VERSION ""

NS_ :

BS_:

BU_: Bms INV U2C VCU

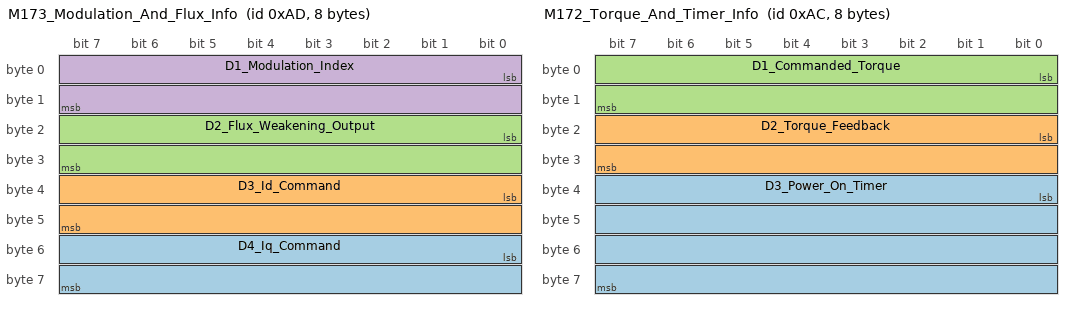
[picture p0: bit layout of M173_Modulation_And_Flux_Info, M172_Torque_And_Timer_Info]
BO_ 173 M173_Modulation_And_Flux_Info: 8 INV
 SG_ D4_Iq_Command : 48|16@1- (0.1,0) [-3276.8|3276.7] "A" Vector__XXX
 SG_ D3_Id_Command : 32|16@1- (0.1,0) [-3276.8|3276.7] "A" Vector__XXX
 SG_ D2_Flux_Weakening_Output : 16|16@1- (0.1,0) [-3276.8|3276.7] "A" Vector__XXX
 SG_ D1_Modulation_Index : 0|16@1- (0.0001,0) [-3.2768|3.2767] "" Vector__XXX

BO_ 172 M172_Torque_And_Timer_Info: 8 INV
 SG_ D3_Power_On_Timer : 32|32@1+ (0.003,0) [0|12884800] "Sec" Vector__XXX
 SG_ D2_Torque_Feedback : 16|16@1- (0.1,0) [-3276.8|3276.7] "Nm" Vector__XXX
 SG_ D1_Commanded_Torque : 0|16@1- (0.1,0) [-3276.8|3276.7] "Nm" Vector__XXX

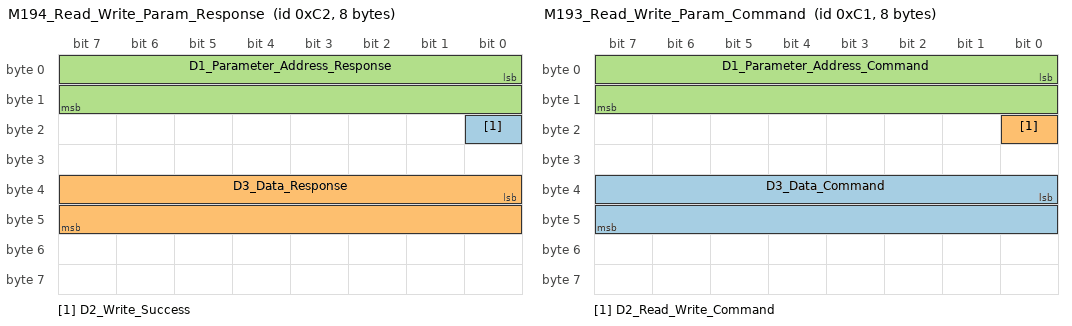
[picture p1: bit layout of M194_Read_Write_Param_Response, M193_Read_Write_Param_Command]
BO_ 194 M194_Read_Write_Param_Response: 8 INV
 SG_ D2_Write_Success : 16|1@1+ (1,0) [0|1] "" Vector__XXX
 SG_ D3_Data_Response : 32|16@1- (1,0) [-32768|32767] "" Vector__XXX
 SG_ D1_Parameter_Address_Response : 0|16@1+ (1,0) [0|65535] "" Vector__XXX

BO_ 193 M193_Read_Write_Param_Command: 8 VCU
 SG_ D3_Data_Command : 32|16@1- (1,0) [-32768|32767] "" Vector__XXX
 SG_ D2_Read_Write_Command : 16|1@1+ (1,0) [0|1] "" Vector__XXX
 SG_ D1_Parameter_Address_Command : 0|16@1+ (1,0) [0|65535] "" Vector__XXX

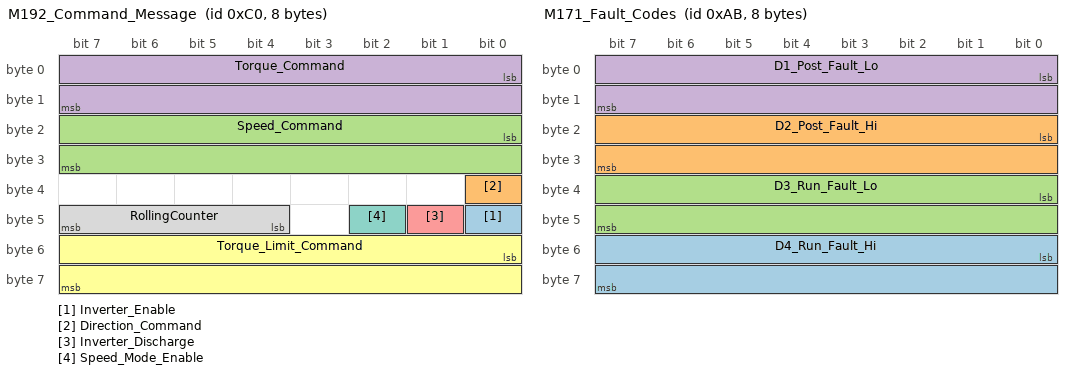
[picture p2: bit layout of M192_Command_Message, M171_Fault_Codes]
BO_ 192 M192_Command_Message: 8 VCU
 SG_ Inverter_Enable : 40|1@1+ (1,0) [0|1] "Bit" Vector__XXX
 SG_ Direction_Command : 32|1@1+ (1,0) [0|1] "Bit" Vector__XXX
 SG_ Speed_Command : 16|16@1- (1,0) [-32768|32767] "rpm" Vector__XXX
 SG_ Torque_Command : 0|16@1- (0.1,0) [-3276.8|3276.7] "Nm" Vector__XXX
 SG_ Inverter_Discharge : 41|1@1+ (1,0) [0|1] "Bit" Vector__XXX
 SG_ Torque_Limit_Command : 48|16@1- (0.1,0) [-3276.8|3276.7] "Nm" Vector__XXX
 SG_ Speed_Mode_Enable : 42|1@1+ (1,0) [0|1] "Bit" Vector__XXX
 SG_ RollingCounter : 44|4@1+ (1,0) [0|15] "Bits" Vector__XXX

BO_ 171 M171_Fault_Codes: 8 INV
 SG_ D4_Run_Fault_Hi : 48|16@1+ (1,0) [0|65535] "" Vector__XXX
 SG_ D2_Post_Fault_Hi : 16|16@1+ (1,0) [0|65535] "" Vector__XXX
 SG_ D3_Run_Fault_Lo : 32|16@1+ (1,0) [0|65535] "" Vector__XXX
 SG_ D1_Post_Fault_Lo : 0|16@1+ (1,0) [0|65535] "" Vector__XXX

BO_ 170 M170_Internal_States: 8 INV
 SG_ D7_Direction_Command : 56|1@1+ (1,0) [0|1] "" Vector__XXX
 SG_ D6_Inverter_Enable_State : 48|1@1+ (1,0) [0|1] "" Vector__XXX
 SG_ D3_Relay_3_Status : 26|1@1+ (1,0) [0|1] "" Vector__XXX
 SG_ D3_Relay_4_Status : 27|1@1+ (1,0) [0|1] "" Vector__XXX
 SG_ D3_Relay_2_Status : 25|1@1+ (1,0) [0|1] "" Vector__XXX
 SG_ D4_Inverter_Run_Mode : 32|1@1+ (1,0) [0|1] "" Vector__XXX
 SG_ D5_Inverter_Command_Mode : 40|1@1+ (1,0) [0|1] "" Vector__XXX
 SG_ D3_Relay_1_Status : 24|1@1+ (1,0) [0|1] "" Vector__XXX
 SG_ D2_Inverter_State : 16|8@1+ (1,0) [0|255] "" Vector__XXX
 SG_ D1_VSM_State : 0|8@1+ (1,0) [0|15] "" Vector__XXX
 SG_ D6_Inverter_Enable_Lockout : 55|1@1+ (1,0) [0|1] "" Vector__XXX
 SG_ D4_Inverter_Discharge_State : 37|3@1+ (1,0) [0|7] "" Vector__XXX
 SG_ D3_Relay_5_Status : 28|1@1+ (1,0) [0|1] "" Vector__XXX
 SG_ D3_Relay_6_Status : 29|1@1+ (1,0) [0|1] "" Vector__XXX
 SG_ D7_BMS_Active : 57|1@1+ (1,0) [0|1] "" Vector__XXX
 SG_ D7_BMS_Torque_Limiting : 58|1@1+ (1,0) [0|1] "" Vector__XXX
 SG_ D7_Max_Speed_Limiting : 59|1@1+ (1,0) [0|1] "" Vector__XXX
 SG_ D7_Low_Speed_Limiting : 61|1@1+ (1,0) [0|1] "" Vector__XXX
 SG_ D5_Rolling_Counter : 44|4@1+ (1,0) [0|15] "" Vector__XXX
 SG_ D1_PWM_Frequency : 8|8@1+ (1,0) [0|255] "kHz" Vector__XXX
 SG_ D6_Start_Mode_Active : 54|1@1+ (1,0) [0|1] "" Vector__XXX

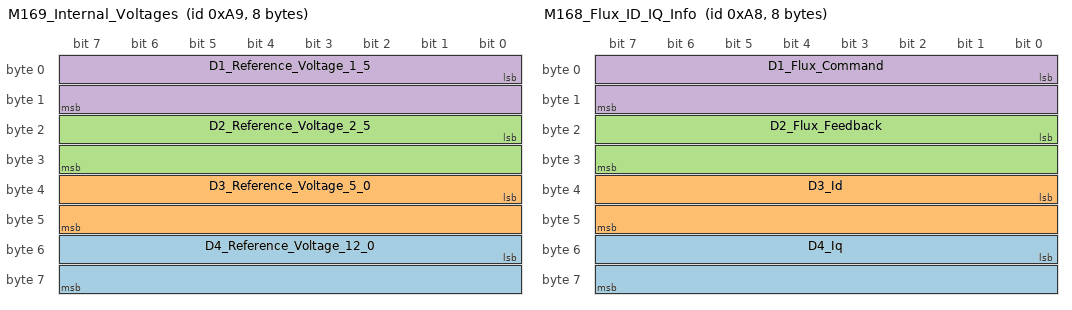
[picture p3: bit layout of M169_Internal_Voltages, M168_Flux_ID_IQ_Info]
BO_ 169 M169_Internal_Voltages: 8 INV
 SG_ D4_Reference_Voltage_12_0 : 48|16@1- (0.01,0) [-327.68|327.67] "V" Vector__XXX
 SG_ D3_Reference_Voltage_5_0 : 32|16@1- (0.01,0) [-327.68|327.67] "V" Vector__XXX
 SG_ D2_Reference_Voltage_2_5 : 16|16@1- (0.01,0) [-327.68|327.67] "V" Vector__XXX
 SG_ D1_Reference_Voltage_1_5 : 0|16@1- (0.01,0) [-327.68|327.67] "V" Vector__XXX

BO_ 168 M168_Flux_ID_IQ_Info: 8 INV
 SG_ D4_Iq : 48|16@1- (0.1,0) [-3276.8|3276.7] "A" Vector__XXX
 SG_ D3_Id : 32|16@1- (0.1,0) [-3276.8|3276.7] "A" Vector__XXX
 SG_ D2_Flux_Feedback : 16|16@1- (0.001,0) [-32.768|32.767] "Wb" Vector__XXX
 SG_ D1_Flux_Command : 0|16@1- (0.001,0) [-32.768|32.767] "Wb" Vector__XXX

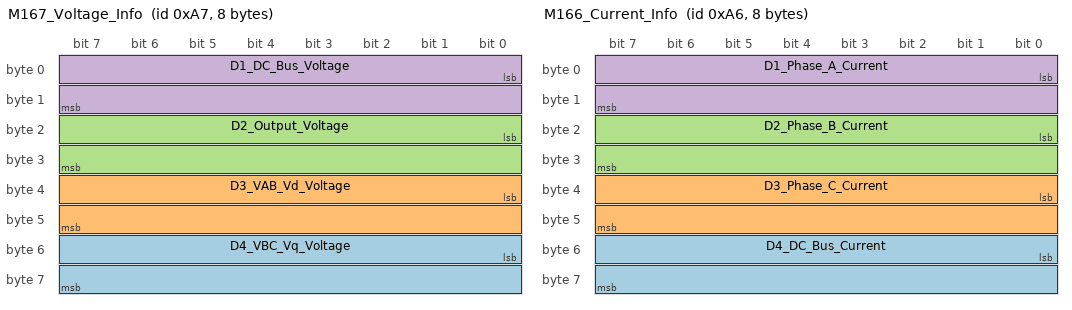
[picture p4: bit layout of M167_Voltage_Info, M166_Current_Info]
BO_ 167 M167_Voltage_Info: 8 INV
 SG_ D4_VBC_Vq_Voltage : 48|16@1- (0.1,0) [-3276.8|3276.7] "V" Vector__XXX
 SG_ D3_VAB_Vd_Voltage : 32|16@1- (0.1,0) [-3276.8|3276.7] "V" Vector__XXX
 SG_ D2_Output_Voltage : 16|16@1- (0.1,0) [-3276.8|3276.7] "V" Vector__XXX
 SG_ D1_DC_Bus_Voltage : 0|16@1- (0.1,0) [-3276.8|3276.7] "V" Vector__XXX

BO_ 166 M166_Current_Info: 8 INV
 SG_ D4_DC_Bus_Current : 48|16@1- (0.1,0) [-3276.8|3276.7] "A" Vector__XXX
 SG_ D3_Phase_C_Current : 32|16@1- (0.1,0) [-3276.8|3276.7] "A" Vector__XXX
 SG_ D2_Phase_B_Current : 16|16@1- (0.1,0) [-3276.8|3276.7] "A" Vector__XXX
 SG_ D1_Phase_A_Current : 0|16@1- (0.1,0) [-3276.8|3276.7] "A" Vector__XXX

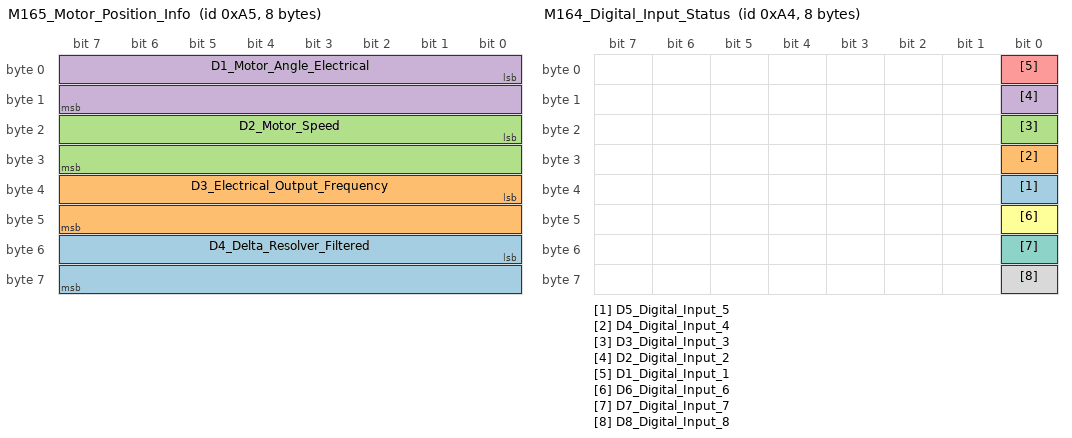
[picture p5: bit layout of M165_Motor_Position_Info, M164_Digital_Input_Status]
BO_ 165 M165_Motor_Position_Info: 8 INV
 SG_ D4_Delta_Resolver_Filtered : 48|16@1- (0.1,0) [-3276.8|3276.7] "deg" Vector__XXX
 SG_ D3_Electrical_Output_Frequency : 32|16@1- (0.1,0) [-3276.8|3276.7] "hz" Vector__XXX
 SG_ D2_Motor_Speed : 16|16@1- (1,0) [-32768|32767] "rpm" Vector__XXX
 SG_ D1_Motor_Angle_Electrical : 0|16@1+ (0.1,0) [0|6553.5] "deg" Vector__XXX

BO_ 164 M164_Digital_Input_Status: 8 INV
 SG_ D5_Digital_Input_5 : 32|1@1+ (1,0) [0|1] "boolean" Vector__XXX
 SG_ D4_Digital_Input_4 : 24|1@1+ (1,0) [0|1] "boolean" Vector__XXX
 SG_ D3_Digital_Input_3 : 16|1@1+ (1,0) [0|1] "boolean" Vector__XXX
 SG_ D2_Digital_Input_2 : 8|1@1+ (1,0) [0|1] "boolean" Vector__XXX
 SG_ D1_Digital_Input_1 : 0|1@1+ (1,0) [0|1] "boolean" Vector__XXX
 SG_ D6_Digital_Input_6 : 40|1@1+ (1,0) [0|1] "boolean" Vector__XXX
 SG_ D7_Digital_Input_7 : 48|1@1+ (1,0) [0|1] "boolean" Vector__XXX
 SG_ D8_Digital_Input_8 : 56|1@1+ (1,0) [0|1] "boolean" Vector__XXX

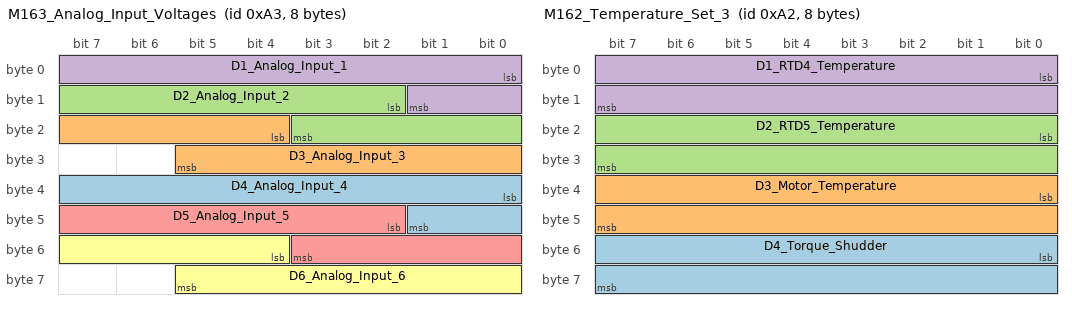
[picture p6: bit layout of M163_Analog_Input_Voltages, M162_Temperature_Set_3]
BO_ 163 M163_Analog_Input_Voltages: 8 INV
 SG_ D4_Analog_Input_4 : 32|10@1+ (0.01,0) [0|10.23] "V" Vector__XXX
 SG_ D3_Analog_Input_3 : 20|10@1+ (0.01,0) [0|10.23] "V" Vector__XXX
 SG_ D2_Analog_Input_2 : 10|10@1+ (0.01,0) [0|10.23] "V" Vector__XXX
 SG_ D1_Analog_Input_1 : 0|10@1+ (0.01,0) [0|10.23] "V" Vector__XXX
 SG_ D5_Analog_Input_5 : 42|10@1+ (0.01,0) [0|10.23] "V" Vector__XXX
 SG_ D6_Analog_Input_6 : 52|10@1+ (0.01,0) [0|10.23] "V" Vector__XXX

BO_ 162 M162_Temperature_Set_3: 8 INV
 SG_ D4_Torque_Shudder : 48|16@1- (0.1,0) [-3276.8|3276.7] "Nm" Vector__XXX
 SG_ D3_Motor_Temperature : 32|16@1- (0.1,0) [-3276.8|3276.7] "degC" Vector__XXX
 SG_ D2_RTD5_Temperature : 16|16@1- (0.1,0) [-3276.8|3276.7] "degC" Vector__XXX
 SG_ D1_RTD4_Temperature : 0|16@1- (0.1,0) [-3276.8|3276.7] "degC" Vector__XXX

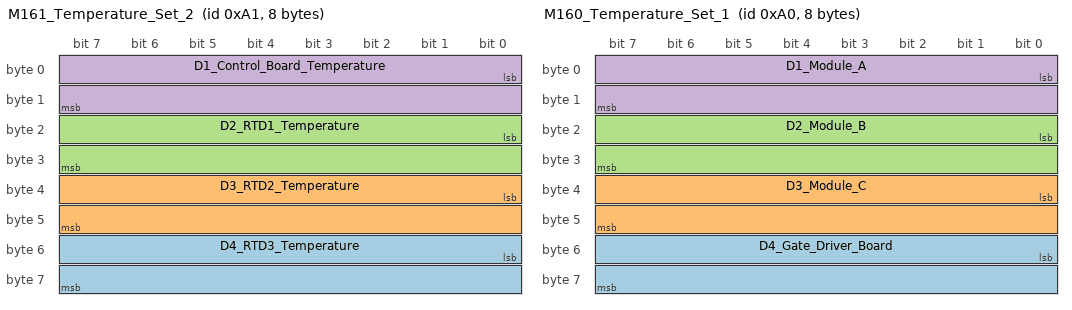
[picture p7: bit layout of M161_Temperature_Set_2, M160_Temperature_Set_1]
BO_ 161 M161_Temperature_Set_2: 8 INV
 SG_ D4_RTD3_Temperature : 48|16@1- (0.1,0) [-3276.8|3276.7] "degC" Vector__XXX
 SG_ D3_RTD2_Temperature : 32|16@1- (0.1,0) [-3276.8|3276.7] "degC" Vector__XXX
 SG_ D2_RTD1_Temperature : 16|16@1- (0.1,0) [-3276.8|3276.7] "degC" Vector__XXX
 SG_ D1_Control_Board_Temperature : 0|16@1- (0.1,0) [-3276.8|3276.7] "degC" Vector__XXX

BO_ 160 M160_Temperature_Set_1: 8 INV
 SG_ D4_Gate_Driver_Board : 48|16@1- (0.1,0) [-3276.8|3276.7] "degC" Vector__XXX
 SG_ D3_Module_C : 32|16@1- (0.1,0) [-3276.8|3276.7] "degC" Vector__XXX
 SG_ D2_Module_B : 16|16@1- (0.1,0) [-3276.8|3276.7] "degC" Vector__XXX
 SG_ D1_Module_A : 0|16@1- (0.1,0) [-3276.8|3276.7] "degC" Vector__XXX

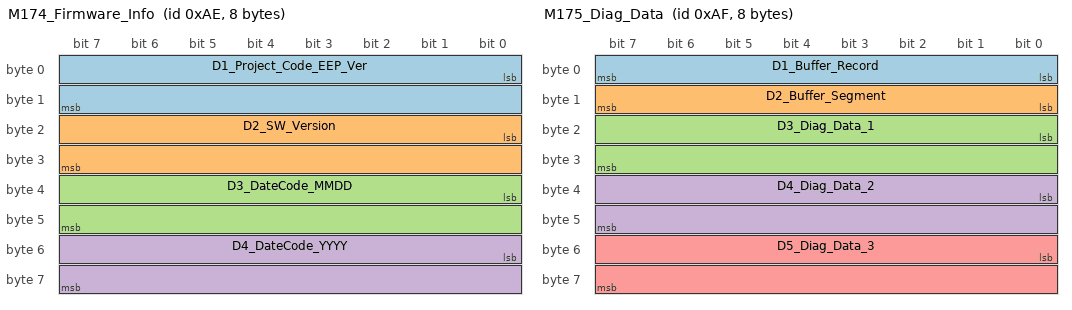
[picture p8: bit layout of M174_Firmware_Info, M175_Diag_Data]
BO_ 174 M174_Firmware_Info: 8 INV
 SG_ D1_Project_Code_EEP_Ver : 0|16@1+ (1,0) [0|65535] "" Vector__XXX
 SG_ D2_SW_Version : 16|16@1+ (1,0) [0|65535] "" Vector__XXX
 SG_ D3_DateCode_MMDD : 32|16@1+ (1,0) [0|65535] "" Vector__XXX
 SG_ D4_DateCode_YYYY : 48|16@1+ (1,0) [0|65535] "" Vector__XXX

BO_ 175 M175_Diag_Data: 8 INV
 SG_ D1_Buffer_Record : 0|8@1+ (1,0) [0|255] "" Vector__XXX
 SG_ D2_Buffer_Segment : 8|8@1+ (1,0) [0|5] "" Vector__XXX
 SG_ D3_Diag_Data_1 : 16|16@1- (1,0) [-32768|32767] "" Vector__XXX
 SG_ D4_Diag_Data_2 : 32|16@1- (1,0) [-32768|32767] "" Vector__XXX
 SG_ D5_Diag_Data_3 : 48|16@1- (1,0) [-32768|32767] "" Vector__XXX

BO_ 471 M187_U2C_Command_Txd: 8 INV
 SG_ D1_ID_Byte : 0|8@1+ (1,0) [0|255] "" Vector__XXX
 SG_ D2_Setpoint_Calc : 8|8@1+ (1,0) [0|255] "" Vector__XXX

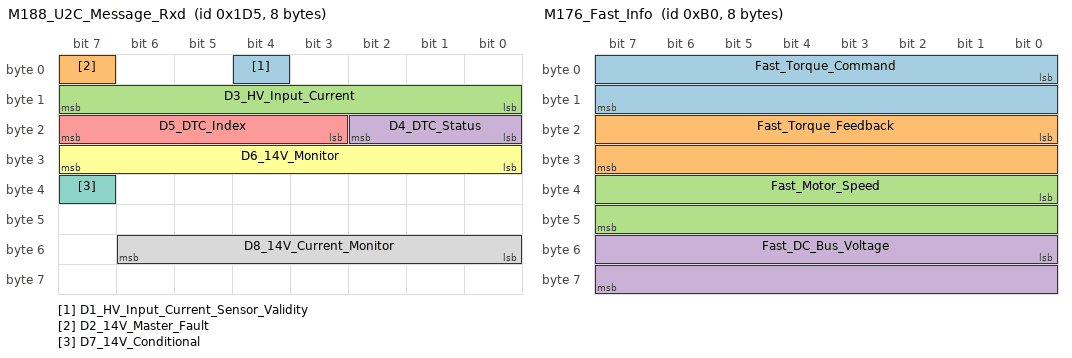
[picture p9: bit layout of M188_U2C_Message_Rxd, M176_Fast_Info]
BO_ 469 M188_U2C_Message_Rxd: 8 U2C
 SG_ D1_HV_Input_Current_Sensor_Validity : 4|1@1+ (1,0) [0|1] "" Vector__XXX
 SG_ D2_14V_Master_Fault : 7|1@1+ (1,0) [0|1] "" Vector__XXX
 SG_ D3_HV_Input_Current : 8|8@1+ (1,0) [0|255] "" Vector__XXX
 SG_ D4_DTC_Status : 16|3@1+ (1,0) [0|7] "" Vector__XXX
 SG_ D5_DTC_Index : 19|5@1+ (1,0) [0|31] "" Vector__XXX
 SG_ D6_14V_Monitor : 24|8@1+ (1,0) [0|255] "" Vector__XXX
 SG_ D7_14V_Conditional : 39|1@1+ (1,0) [0|1] "" Vector__XXX
 SG_ D8_14V_Current_Monitor : 48|7@1+ (1,0) [0|127] "" Vector__XXX

BO_ 514 BMS_Current_Limit: 8 BMS
 SG_ D1_Max_Discharge_Current : 0|16@1+ (1,0) [0|1000] "A" Vector__XXX
 SG_ D2_Max_Charge_Current : 16|16@1+ (1,0) [0|1000] "A" Vector__XXX

BO_ 176 M176_Fast_Info: 8 INV
 SG_ Fast_Torque_Command : 0|16@1- (0.1,0) [-3276.8|3276.7] "Nm" Vector__XXX
 SG_ Fast_Torque_Feedback : 16|16@1- (0.1,0) [-3276.8|3276.7] "Nm" Vector__XXX
 SG_ Fast_Motor_Speed : 32|16@1- (1,0) [-32768|32767] "rpm" Vector__XXX
 SG_ Fast_DC_Bus_Voltage : 48|16@1- (0.1,0) [-3276.8|3276.7] "V" Vector__XXX

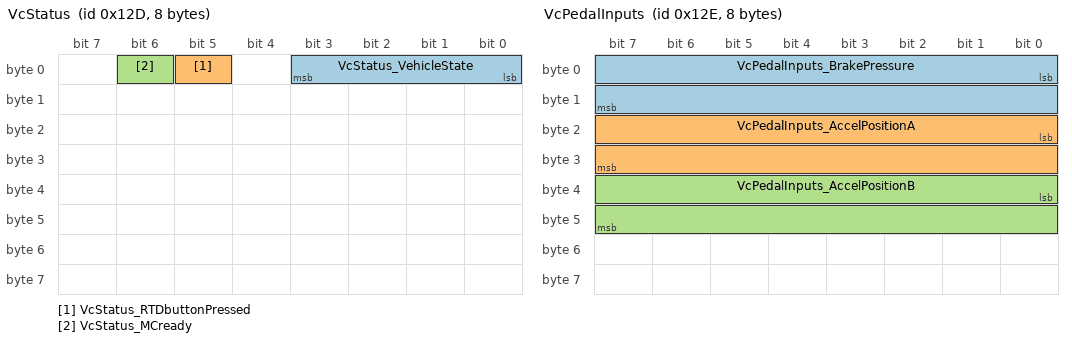
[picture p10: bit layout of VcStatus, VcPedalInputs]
BO_ 301 VcStatus: 8 VCU
 SG_ VcStatus_VehicleState : 0|4@1+ (1,0) [0|15] "" Vector__XXX
 SG_ VcStatus_RTDbuttonPressed : 5|1@1+ (1,0) [0|1] "" Vector_XXX
 SG_ VcStatus_MCready : 6|1@1+ (1,0) [0|1] "" Vector_XXX

BO_ 302 VcPedalInputs: 8 VCU
 SG_ VcPedalInputs_BrakePressure : 0|16@1+ (0.1,0) [0|3000] "psi" Vector__XXX
 SG_ VcPedalInputs_AccelPositionA : 16|16@1+ (0.1,0) [0|100] "%" Vector__XXX
 SG_ VcPedalInputs_AccelPositionB : 32|16@1+ (0.1,0) [0|100] "%" Vector__XXX

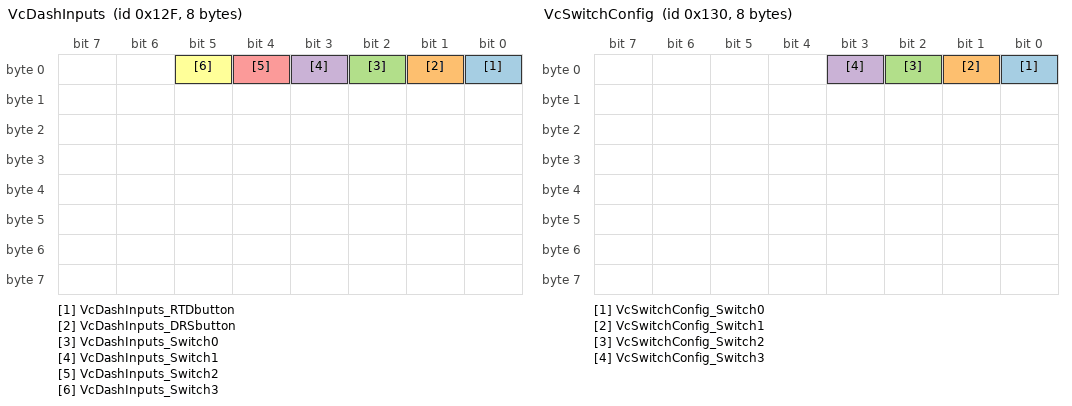
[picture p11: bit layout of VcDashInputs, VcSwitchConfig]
BO_ 303 VcDashInputs: 8 VCU
 SG_ VcDashInputs_RTDbutton : 0|1@1+ (1,0) [0|1] "" Vector__XXX
 SG_ VcDashInputs_DRSbutton : 1|1@1+ (1,0) [0|1] "" Vector__XXX
 SG_ VcDashInputs_Switch0 : 2|1@1+ (1,0) [0|1] "" Vector__XXX
 SG_ VcDashInputs_Switch1 : 3|1@1+ (1,0) [0|1] "" Vector__XXX
 SG_ VcDashInputs_Switch2 : 4|1@1+ (1,0) [0|1] "" Vector__XXX
 SG_ VcDashInputs_Switch3 : 5|1@1+ (1,0) [0|1] "" Vector__XXX

BO_ 304 VcSwitchConfig: 8 VCU
 SG_ VcSwitchConfig_Switch0 : 0|1@1+ (1,0) [0|1] "" Vector__XXX
 SG_ VcSwitchConfig_Switch1 : 1|1@1+ (1,0) [0|1] "" Vector__XXX
 SG_ VcSwitchConfig_Switch2 : 2|1@1+ (1,0) [0|1] "" Vector__XXX
 SG_ VcSwitchConfig_Switch3 : 3|1@1+ (1,0) [0|1] "" Vector__XXX

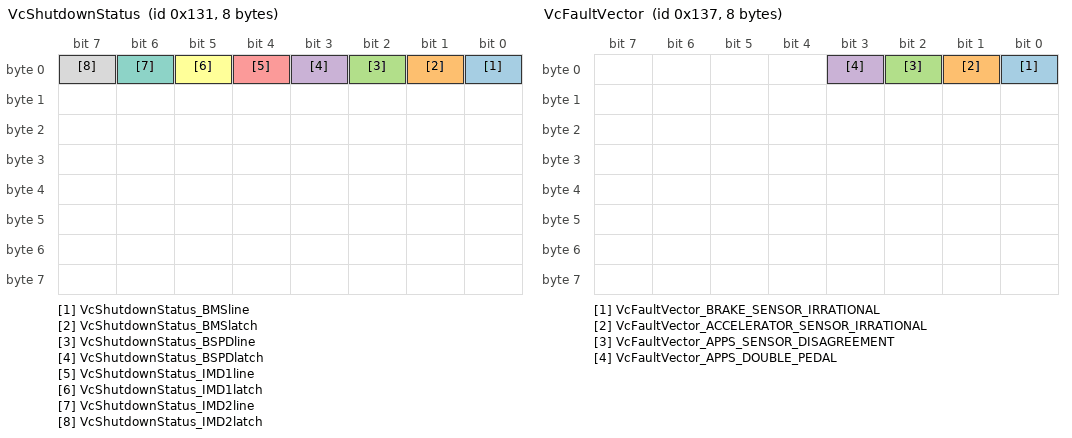
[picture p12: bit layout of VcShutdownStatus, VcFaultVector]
BO_ 305 VcShutdownStatus: 8 VCU
 SG_ VcShutdownStatus_BMSline : 0|1@1+ (1,0) [0|1] "" Vector__XXX
 SG_ VcShutdownStatus_BMSlatch : 1|1@1+ (1,0) [0|1] "" Vector__XXX
 SG_ VcShutdownStatus_BSPDline : 2|1@1+ (1,0) [0|1] "" Vector__XXX
 SG_ VcShutdownStatus_BSPDlatch : 3|1@1+ (1,0) [0|1] "" Vector__XXX
 SG_ VcShutdownStatus_IMD1line : 4|1@1+ (1,0) [0|1] "" Vector__XXX
 SG_ VcShutdownStatus_IMD1latch : 5|1@1+ (1,0) [0|1] "" Vector__XXX
 SG_ VcShutdownStatus_IMD2line : 6|1@1+ (1,0) [0|1] "" Vector__XXX
 SG_ VcShutdownStatus_IMD2latch : 7|1@1+ (1,0) [0|1] "" Vector__XXX

BO_ 311 VcFaultVector: 8 VCU
SG_ VcFaultVector_BRAKE_SENSOR_IRRATIONAL: 0|1@1+ (1,0) [0|1] "" Vector__XXX
SG_ VcFaultVector_ACCELERATOR_SENSOR_IRRATIONAL: 1|1@1+ (1,0) [0|1] "" Vector__XXX
SG_ VcFaultVector_APPS_SENSOR_DISAGREEMENT: 2|1@1+ (1,0) [0|1] "" Vector__XXX
SG_ VcFaultVector_APPS_DOUBLE_PEDAL: 3|1@1+ (1,0) [0|1] "" Vector__XXX

BO_ 306 VcFaultAlert: 8 VCU
 SG_ VcFaultAlert_code M : 0|6@1+ (1,0) [0|63] "" Vector__XXX
 SG_ VcFaultAlert_brakePressure m0 : 7|16@1+ (0.1,0) [0|3000] "psi" Vector__XXX
 SG_ VcFaultAlert_accelVoltage m1 : 7|16@1+ (0.01,0) [0|5] "V" Vector__XXX

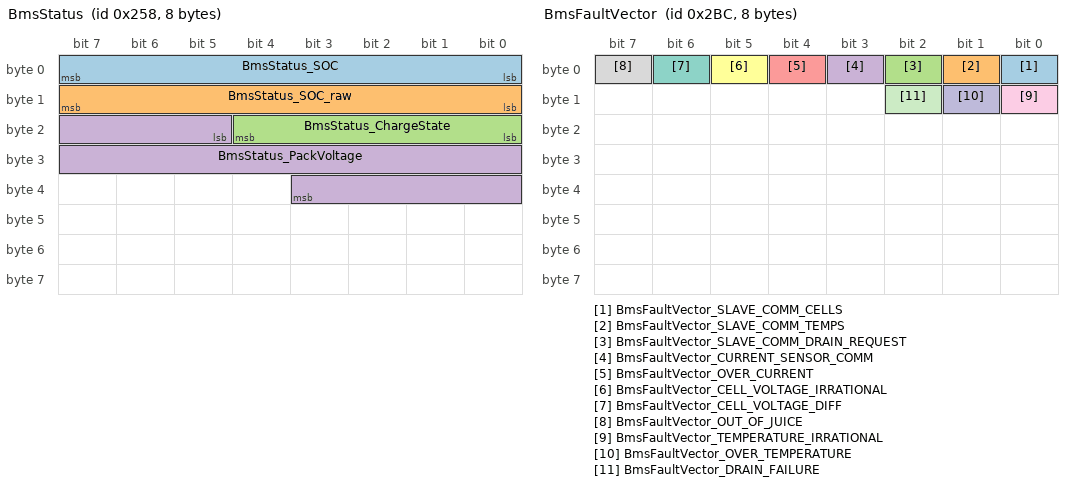
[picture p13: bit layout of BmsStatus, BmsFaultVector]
BO_ 600 BmsStatus: 8  Bms
 SG_ BmsStatus_SOC: 0|8@1+ (1,0) [0|100] "%" Vector__XXX
 SG_ BmsStatus_SOC_raw: 8|8@1+ (1,0) [0|100] "%" Vector__XXX
 SG_ BmsStatus_ChargeState: 16|5@1+ (1,0) [0|4] "" Vector__XXX
 SG_ BmsStatus_PackVoltage: 21|15@1+ (0.1,0) [0|400] "V" Vector__XXX

BO_ 700 BmsFaultVector: 8 Bms
 SG_ BmsFaultVector_SLAVE_COMM_CELLS : 0|1@1+ (1,0) [0|1] "" Vector__XXX
 SG_ BmsFaultVector_SLAVE_COMM_TEMPS : 1|1@1+ (1,0) [0|1] "" Vector__XXX
 SG_ BmsFaultVector_SLAVE_COMM_DRAIN_REQUEST : 2|1@1+ (1,0) [0|1] "" Vector__XXX
 SG_ BmsFaultVector_CURRENT_SENSOR_COMM : 3|1@1+ (1,0) [0|1] "" Vector__XXX
 SG_ BmsFaultVector_OVER_CURRENT : 4|1@1+ (1,0) [0|1] "" Vector__XXX
 SG_ BmsFaultVector_CELL_VOLTAGE_IRRATIONAL : 5|1@1+ (1,0) [0|1] "" Vector__XXX
 SG_ BmsFaultVector_CELL_VOLTAGE_DIFF : 6|1@1+ (1,0) [0|1] "" Vector__XXX
 SG_ BmsFaultVector_OUT_OF_JUICE : 7|1@1+ (1,0) [0|1] "" Vector__XXX
 SG_ BmsFaultVector_TEMPERATURE_IRRATIONAL: 8|1@1+ (1,0) [0|1] "" Vector__XXX
 SG_ BmsFaultVector_OVER_TEMPERATURE: 9|1@1+ (1,0) [0|1] "" Vector__XXX
 SG_ BmsFaultVector_DRAIN_FAILURE: 10|1@1+ (1,0) [0|1] "" Vector__XXX

BO_ 701 BmsFaultAlert: 8 Bms
 SG_ BmsFaultAlert_code M : 0|6@1+ (1,0) [0|63] "" Vector__XXX
 SG_ BmsFaultAlert_cell_comm_slave_board_num m0: 6|8@1+ (1,0) [0|255] "" Vector__XXX
 SG_ BmsFaultAlert_temp_comm_slave_board_num m1: 6|8@1+ (1,0) [0|255] "" Vector__XXX
 SG_ BmsFaultAlert_drain_comm_slave_board_num m2: 6|8@1+ (1,0) [0|255] "" Vector__XXX
 SG_ BmsFaultAlert_adc_error_code m3: 6|8@1+ (1,0) [0|255] "" Vector__XXX
 SG_ BmsFaultAlert_current m4: 6|32@1+ (0.001,0) [0|2000] "A" Vector__XXX
 SG_ BmsFaultAlert_irrational_voltage m5: 6|9@1+ (0.01,0) [0|5.12] "V" Vector__XXX
 SG_ BmsFaultAlert_voltage_diff m6: 6|9@1+ (0.01,0) [0|5.12] "V" Vector__XXX
 SG_ BmsFaultAlert_lowest_cell_voltage m7: 6|9@1+ (0.01,0) [0|5.12] "V" Vector__XXX
 SG_ BmsFaultAlert_irrational_temperature m8: 6|16@1+ (0.01,0) [-327.68|327.67] "V" Vector__XXX
 SG_ BmsFaultAlert_over_temperature m9: 6|16@1+ (0.01,0) [-327.68|327.67] "V" Vector__XXX
 SG_ BmsFaultAlert_failed_drain_cell m10: 6|8@1+ (1,0) [0|255] "" Vector__XXX

BO_ 702 BmsVoltages: 8 Bms
 SG_ BmsVoltages_mux M : 0|8@1+ (1,0) [0|255] "" Vector__XXX
 SG_ BmsVoltages_Cell0 m0 : 8|9@1+ (0.01,0) [0|5.12] "V" Vector__XXX
 SG_ BmsVoltages_Cell1 m0 : 17|9@1+ (0.01,0) [0|5.12] "V" Vector__XXX
 SG_ BmsVoltages_Cell2 m0 : 26|9@1+ (0.01,0) [0|5.12] "V" Vector__XXX
 SG_ BmsVoltages_Cell3 m0 : 35|9@1+ (0.01,0) [0|5.12] "V" Vector__XXX
 SG_ BmsVoltages_Cell4 m0 : 44|9@1+ (0.01,0) [0|5.12] "V" Vector__XXX
 SG_ BmsVoltages_Cell5 m0 : 53|9@1+ (0.01,0) [0|5.12] "V" Vector__XXX
 SG_ BmsVoltages_Cell6 m1 : 8|9@1+ (0.01,0) [0|5.12] "V" Vector__XXX
 SG_ BmsVoltages_Cell7 m1 : 17|9@1+ (0.01,0) [0|5.12] "V" Vector__XXX
 SG_ BmsVoltages_Cell8 m1 : 26|9@1+ (0.01,0) [0|5.12] "V" Vector__XXX
 SG_ BmsVoltages_Cell9 m1 : 35|9@1+ (0.01,0) [0|5.12] "V" Vector__XXX
 SG_ BmsVoltages_Cell10 m1 : 44|9@1+ (0.01,0) [0|5.12] "V" Vector__XXX
 SG_ BmsVoltages_Cell11 m1 : 53|9@1+ (0.01,0) [0|5.12] "V" Vector__XXX
 SG_ BmsVoltages_Cell12 m2 : 8|9@1+ (0.01,0) [0|5.12] "V" Vector__XXX
 SG_ BmsVoltages_Cell13 m2 : 17|9@1+ (0.01,0) [0|5.12] "V" Vector__XXX
 SG_ BmsVoltages_Cell14 m2 : 26|9@1+ (0.01,0) [0|5.12] "V" Vector__XXX
 SG_ BmsVoltages_Cell15 m2 : 35|9@1+ (0.01,0) [0|5.12] "V" Vector__XXX
 SG_ BmsVoltages_Cell16 m2 : 44|9@1+ (0.01,0) [0|5.12] "V" Vector__XXX
 SG_ BmsVoltages_Cell17 m2 : 53|9@1+ (0.01,0) [0|5.12] "V" Vector__XXX
 SG_ BmsVoltages_Cell18 m3 : 8|9@1+ (0.01,0) [0|5.12] "V" Vector__XXX
 SG_ BmsVoltages_Cell19 m3 : 17|9@1+ (0.01,0) [0|5.12] "V" Vector__XXX
 SG_ BmsVoltages_Cell20 m3 : 26|9@1+ (0.01,0) [0|5.12] "V" Vector__XXX
 SG_ BmsVoltages_Cell21 m3 : 35|9@1+ (0.01,0) [0|5.12] "V" Vector__XXX
 SG_ BmsVoltages_Cell22 m3 : 44|9@1+ (0.01,0) [0|5.12] "V" Vector__XXX
 SG_ BmsVoltages_Cell23 m3 : 53|9@1+ (0.01,0) [0|5.12] "V" Vector__XXX
 SG_ BmsVoltages_Cell24 m4 : 8|9@1+ (0.01,0) [0|5.12] "V" Vector__XXX
 SG_ BmsVoltages_Cell25 m4: 17|9@1+ (0.01,0) [0|5.12] "V" Vector__XXX
 SG_ BmsVoltages_Cell26 m4: 26|9@1+ (0.01,0) [0|5.12] "V" Vector__XXX
 SG_ BmsVoltages_Cell27 m4: 35|9@1+ (0.01,0) [0|5.12] "V" Vector__XXX
 SG_ BmsVoltages_Cell28 m4: 44|9@1+ (0.01,0) [0|5.12] "V" Vector__XXX
 SG_ BmsVoltages_Cell29 m4: 53|9@1+ (0.01,0) [0|5.12] "V" Vector__XXX
 SG_ BmsVoltages_Cell30 m5: 8|9@1+ (0.01,0) [0|5.12] "V" Vector__XXX
 SG_ BmsVoltages_Cell31 m5: 17|9@1+ (0.01,0) [0|5.12] "V" Vector__XXX
 SG_ BmsVoltages_Cell32 m5: 26|9@1+ (0.01,0) [0|5.12] "V" Vector__XXX
 SG_ BmsVoltages_Cell33 m5: 35|9@1+ (0.01,0) [0|5.12] "V" Vector__XXX
 SG_ BmsVoltages_Cell34 m5: 44|9@1+ (0.01,0) [0|5.12] "V" Vector__XXX
 SG_ BmsVoltages_Cell35 m5: 53|9@1+ (0.01,0) [0|5.12] "V" Vector__XXX
 SG_ BmsVoltages_Cell36 m6: 8|9@1+ (0.01,0) [0|5.12] "V" Vector__XXX
 SG_ BmsVoltages_Cell37 m6: 17|9@1+ (0.01,0) [0|5.12] "V" Vector__XXX
 SG_ BmsVoltages_Cell38 m6: 26|9@1+ (0.01,0) [0|5.12] "V" Vector__XXX
 SG_ BmsVoltages_Cell39 m6: 35|9@1+ (0.01,0) [0|5.12] "V" Vector__XXX
 SG_ BmsVoltages_Cell40 m6: 44|9@1+ (0.01,0) [0|5.12] "V" Vector__XXX
 SG_ BmsVoltages_Cell41 m6: 53|9@1+ (0.01,0) [0|5.12] "V" Vector__XXX
 SG_ BmsVoltages_Cell42 m7: 8|9@1+ (0.01,0) [0|5.12] "V" Vector__XXX
 SG_ BmsVoltages_Cell43 m7: 17|9@1+ (0.01,0) [0|5.12] "V" Vector__XXX
 SG_ BmsVoltages_Cell44 m7: 26|9@1+ (0.01,0) [0|5.12] "V" Vector__XXX
 SG_ BmsVoltages_Cell45 m7: 35|9@1+ (0.01,0) [0|5.12] "V" Vector__XXX
 SG_ BmsVoltages_Cell46 m7: 44|9@1+ (0.01,0) [0|5.12] "V" Vector__XXX
 SG_ BmsVoltages_Cell47 m7: 53|9@1+ (0.01,0) [0|5.12] "V" Vector__XXX
 SG_ BmsVoltages_Cell48 m8: 8|9@1+ (0.01,0) [0|5.12] "V" Vector__XXX
 SG_ BmsVoltages_Cell49 m8: 17|9@1+ (0.01,0) [0|5.12] "V" Vector__XXX
 SG_ BmsVoltages_Cell50 m8: 26|9@1+ (0.01,0) [0|5.12] "V" Vector__XXX
 SG_ BmsVoltages_Cell51 m8: 35|9@1+ (0.01,0) [0|5.12] "V" Vector__XXX
 SG_ BmsVoltages_Cell52 m8: 44|9@1+ (0.01,0) [0|5.12] "V" Vector__XXX
 SG_ BmsVoltages_Cell53 m8: 53|9@1+ (0.01,0) [0|5.12] "V" Vector__XXX
 SG_ BmsVoltages_Cell54 m9: 8|9@1+ (0.01,0) [0|5.12] "V" Vector__XXX
 SG_ BmsVoltages_Cell55 m9: 17|9@1+ (0.01,0) [0|5.12] "V" Vector__XXX
 SG_ BmsVoltages_Cell56 m9: 26|9@1+ (0.01,0) [0|5.12] "V" Vector__XXX
 SG_ BmsVoltages_Cell57 m9: 35|9@1+ (0.01,0) [0|5.12] "V" Vector__XXX
 SG_ BmsVoltages_Cell58 m9: 44|9@1+ (0.01,0) [0|5.12] "V" Vector__XXX
 SG_ BmsVoltages_Cell59 m9: 53|9@1+ (0.01,0) [0|5.12] "V" Vector__XXX
 SG_ BmsVoltages_Cell60 m10: 8|9@1+ (0.01,0) [0|5.12] "V" Vector__XXX
 SG_ BmsVoltages_Cell61 m10: 17|9@1+ (0.01,0) [0|5.12] "V" Vector__XXX
 SG_ BmsVoltages_Cell62 m10: 26|9@1+ (0.01,0) [0|5.12] "V" Vector__XXX
 SG_ BmsVoltages_Cell63 m10: 35|9@1+ (0.01,0) [0|5.12] "V" Vector__XXX
 SG_ BmsVoltages_Cell64 m10: 44|9@1+ (0.01,0) [0|5.12] "V" Vector__XXX
 SG_ BmsVoltages_Cell65 m10: 53|9@1+ (0.01,0) [0|5.12] "V" Vector__XXX
 SG_ BmsVoltages_Cell66 m11: 8|9@1+ (0.01,0) [0|5.12] "V" Vector__XXX
 SG_ BmsVoltages_Cell67 m11: 17|9@1+ (0.01,0) [0|5.12] "V" Vector__XXX
 SG_ BmsVoltages_Cell68 m11: 26|9@1+ (0.01,0) [0|5.12] "V" Vector__XXX
 SG_ BmsVoltages_Cell69 m11: 35|9@1+ (0.01,0) [0|5.12] "V" Vector__XXX
 SG_ BmsVoltages_Cell70 m11: 44|9@1+ (0.01,0) [0|5.12] "V" Vector__XXX
 SG_ BmsVoltages_Cell71 m11: 53|9@1+ (0.01,0) [0|5.12] "V" Vector__XXX
 SG_ BmsVoltages_Cell72 m12: 8|9@1+ (0.01,0) [0|5.12] "V" Vector__XXX
 SG_ BmsVoltages_Cell73 m12: 17|9@1+ (0.01,0) [0|5.12] "V" Vector__XXX
 SG_ BmsVoltages_Cell74 m12: 26|9@1+ (0.01,0) [0|5.12] "V" Vector__XXX
 SG_ BmsVoltages_Cell75 m12: 35|9@1+ (0.01,0) [0|5.12] "V" Vector__XXX
 SG_ BmsVoltages_Cell76 m12: 44|9@1+ (0.01,0) [0|5.12] "V" Vector__XXX
 SG_ BmsVoltages_Cell77 m12: 53|9@1+ (0.01,0) [0|5.12] "V" Vector__XXX
 SG_ BmsVoltages_Cell78 m13: 8|9@1+ (0.01,0) [0|5.12] "V" Vector__XXX
 SG_ BmsVoltages_Cell79 m13: 17|9@1+ (0.01,0) [0|5.12] "V" Vector__XXX
 SG_ BmsVoltages_Cell80 m13: 26|9@1+ (0.01,0) [0|5.12] "V" Vector__XXX
 SG_ BmsVoltages_Cell81 m13: 35|9@1+ (0.01,0) [0|5.12] "V" Vector__XXX
 SG_ BmsVoltages_Cell82 m13: 44|9@1+ (0.01,0) [0|5.12] "V" Vector__XXX
 SG_ BmsVoltages_Cell83 m13: 53|9@1+ (0.01,0) [0|5.12] "V" Vector__XXX
 SG_ BmsVoltages_Cell84 m14: 8|9@1+ (0.01,0) [0|5.12] "V" Vector__XXX
 SG_ BmsVoltages_Cell85 m14: 17|9@1+ (0.01,0) [0|5.12] "V" Vector__XXX
 SG_ BmsVoltages_Cell86 m14: 26|9@1+ (0.01,0) [0|5.12] "V" Vector__XXX
 SG_ BmsVoltages_Cell87 m14: 35|9@1+ (0.01,0) [0|5.12] "V" Vector__XXX
 SG_ BmsVoltages_Cell88 m14: 44|9@1+ (0.01,0) [0|5.12] "V" Vector__XXX
 SG_ BmsVoltages_Cell89 m14: 53|9@1+ (0.01,0) [0|5.12] "V" Vector__XXX

BO_ 703 BmsThermistorVoltages: 8 Bms
 SG_ BmsThermistorVoltages_mux M : 0|2@1+ (1,0) [0|3] "" Vector__XXX
 SG_ BmsThermistorVoltages_tm0 m0: 2|9@1+ (0.01,0) [0|5.12] "V" Vector__XXX
 SG_ BmsThermistorVoltages_tm1 m0: 11|9@1+ (0.01,0) [0|5.12] "V" Vector__XXX
 SG_ BmsThermistorVoltages_tm2 m0: 20|9@1+ (0.01,0) [0|5.12] "V" Vector__XXX
 SG_ BmsThermistorVoltages_tm3 m0: 29|9@1+ (0.01,0) [0|5.12] "V" Vector__XXX
 SG_ BmsThermistorVoltages_tm4 m0: 38|9@1+ (0.01,0) [0|5.12] "V" Vector__XXX
 SG_ BmsThermistorVoltages_tm5 m0: 47|9@1+ (0.01,0) [0|5.12] "V" Vector__XXX
 SG_ BmsThermistorVoltages_tm6 m1: 2|9@1+ (0.01,0) [0|5.12] "V" Vector__XXX
 SG_ BmsThermistorVoltages_tm7 m1: 11|9@1+ (0.01,0) [0|5.12] "V" Vector__XXX
 SG_ BmsThermistorVoltages_tm8 m1: 20|9@1+ (0.01,0) [0|5.12] "V" Vector__XXX
 SG_ BmsThermistorVoltages_tm9 m1: 29|9@1+ (0.01,0) [0|5.12] "V" Vector__XXX
 SG_ BmsThermistorVoltages_tm10 m1: 38|9@1+ (0.01,0) [0|5.12] "V" Vector__XXX
 SG_ BmsThermistorVoltages_tm11 m1: 47|9@1+ (0.01,0) [0|5.12] "V" Vector__XXX
 SG_ BmsThermistorVoltages_tm12 m2: 2|9@1+ (0.01,0) [0|5.12] "V" Vector__XXX
 SG_ BmsThermistorVoltages_tm13 m2: 11|9@1+ (0.01,0) [0|5.12] "V" Vector__XXX
 SG_ BmsThermistorVoltages_tm14 m2: 20|9@1+ (0.01,0) [0|5.12] "V" Vector__XXX
 SG_ BmsThermistorVoltages_tm15 m2: 29|9@1+ (0.01,0) [0|5.12] "V" Vector__XXX
 SG_ BmsThermistorVoltages_tm16 m2: 38|9@1+ (0.01,0) [0|5.12] "V" Vector__XXX
 SG_ BmsThermistorVoltages_tm17 m2: 47|9@1+ (0.01,0) [0|5.12] "V" Vector__XXX
 SG_ BmsThermistorVoltages_tm18 m3: 2|9@1+ (0.01,0) [0|5.12] "V" Vector__XXX
 SG_ BmsThermistorVoltages_tm19 m3: 11|9@1+ (0.01,0) [0|5.12] "V" Vector__XXX

BO_ 704 BmsTemperatures: 8 Bms
 SG_ BmsTemperatures_mux M : 0|2@1+ (1,0) [0|3] "" Vector__XXX
 SG_ BmsTemperatures_0 m0: 2|8@1- (1,0) [-128|127] "C" Vector__XXX
 SG_ BmsTemperatures_1 m0: 10|8@1- (1,0) [-128|127] "C" Vector__XXX
 SG_ BmsTemperatures_2 m0: 18|8@1- (1,0) [-128|127] "C" Vector__XXX
 SG_ BmsTemperatures_3 m0: 26|8@1- (1,0) [-128|127] "C" Vector__XXX
 SG_ BmsTemperatures_4 m0: 34|8@1- (1,0) [-128|127] "C" Vector__XXX
 SG_ BmsTemperatures_5 m0: 42|8@1- (1,0) [-128|127] "C" Vector__XXX
 SG_ BmsTemperatures_6 m0: 50|8@1- (1,0) [-128|127] "C" Vector__XXX
 SG_ BmsTemperatures_7 m1: 2|8@1- (1,0) [-128|127] "C" Vector__XXX
 SG_ BmsTemperatures_8 m1: 10|8@1- (1,0) [-128|127] "C" Vector__XXX
 SG_ BmsTemperatures_9 m1: 18|8@1- (1,0) [-128|127] "C" Vector__XXX
 SG_ BmsTemperatures_10 m1: 26|8@1- (1,0) [-128|127] "C" Vector__XXX
 SG_ BmsTemperatures_11 m1: 34|8@1- (1,0) [-128|127] "C" Vector__XXX
 SG_ BmsTemperatures_12 m1: 42|8@1- (1,0) [-128|127] "C" Vector__XXX
 SG_ BmsTemperatures_13 m1: 50|8@1- (1,0) [-128|127] "C" Vector__XXX
 SG_ BmsTemperatures_14 m2: 2|8@1- (1,0) [-128|127] "C" Vector__XXX
 SG_ BmsTemperatures_15 m2: 10|8@1- (1,0) [-128|127] "C" Vector__XXX
 SG_ BmsTemperatures_16 m2: 18|8@1- (1,0) [-128|127] "C" Vector__XXX
 SG_ BmsTemperatures_17 m2: 26|8@1- (1,0) [-128|127] "C" Vector__XXX
 SG_ BmsTemperatures_18 m2: 34|8@1- (1,0) [-128|127] "C" Vector__XXX
 SG_ BmsTemperatures_19 m2: 42|8@1- (1,0) [-128|127] "C" Vector__XXX

BO_ 800 BmsDrainStatusA: 8 Bms
 SG_ BmsDrainStatusA_Cell0: 0|1@1+ (1,0) [0|1] "" Vector__XXX
 SG_ BmsDrainStatusA_Cell1: 1|1@1+ (1,0) [0|1] "" Vector__XXX
 SG_ BmsDrainStatusA_Cell2: 2|1@1+ (1,0) [0|1] "" Vector__XXX
 SG_ BmsDrainStatusA_Cell3: 3|1@1+ (1,0) [0|1] "" Vector__XXX
 SG_ BmsDrainStatusA_Cell4: 4|1@1+ (1,0) [0|1] "" Vector__XXX
 SG_ BmsDrainStatusA_Cell5: 5|1@1+ (1,0) [0|1] "" Vector__XXX
 SG_ BmsDrainStatusA_Cell6: 6|1@1+ (1,0) [0|1] "" Vector__XXX
 SG_ BmsDrainStatusA_Cell7: 7|1@1+ (1,0) [0|1] "" Vector__XXX
 SG_ BmsDrainStatusA_Cell8: 8|1@1+ (1,0) [0|1] "" Vector__XXX
 SG_ BmsDrainStatusA_Cell9: 9|1@1+ (1,0) [0|1] "" Vector__XXX
 SG_ BmsDrainStatusA_Cell10: 10|1@1+ (1,0) [0|1] "" Vector__XXX
 SG_ BmsDrainStatusA_Cell11: 11|1@1+ (1,0) [0|1] "" Vector__XXX
 SG_ BmsDrainStatusA_Cell12: 12|1@1+ (1,0) [0|1] "" Vector__XXX
 SG_ BmsDrainStatusA_Cell13: 13|1@1+ (1,0) [0|1] "" Vector__XXX
 SG_ BmsDrainStatusA_Cell14: 14|1@1+ (1,0) [0|1] "" Vector__XXX
 SG_ BmsDrainStatusA_Cell15: 15|1@1+ (1,0) [0|1] "" Vector__XXX
 SG_ BmsDrainStatusA_Cell16: 16|1@1+ (1,0) [0|1] "" Vector__XXX
 SG_ BmsDrainStatusA_Cell17: 17|1@1+ (1,0) [0|1] "" Vector__XXX
 SG_ BmsDrainStatusA_Cell18: 18|1@1+ (1,0) [0|1] "" Vector__XXX
 SG_ BmsDrainStatusA_Cell19: 19|1@1+ (1,0) [0|1] "" Vector__XXX
 SG_ BmsDrainStatusA_Cell20: 20|1@1+ (1,0) [0|1] "" Vector__XXX
 SG_ BmsDrainStatusA_Cell21: 21|1@1+ (1,0) [0|1] "" Vector__XXX
 SG_ BmsDrainStatusA_Cell22: 22|1@1+ (1,0) [0|1] "" Vector__XXX
 SG_ BmsDrainStatusA_Cell23: 23|1@1+ (1,0) [0|1] "" Vector__XXX
 SG_ BmsDrainStatusA_Cell24: 24|1@1+ (1,0) [0|1] "" Vector__XXX
 SG_ BmsDrainStatusA_Cell25: 25|1@1+ (1,0) [0|1] "" Vector__XXX
 SG_ BmsDrainStatusA_Cell26: 26|1@1+ (1,0) [0|1] "" Vector__XXX
 SG_ BmsDrainStatusA_Cell27: 27|1@1+ (1,0) [0|1] "" Vector__XXX
 SG_ BmsDrainStatusA_Cell28: 28|1@1+ (1,0) [0|1] "" Vector__XXX
 SG_ BmsDrainStatusA_Cell29: 29|1@1+ (1,0) [0|1] "" Vector__XXX
 SG_ BmsDrainStatusA_Cell30: 30|1@1+ (1,0) [0|1] "" Vector__XXX
 SG_ BmsDrainStatusA_Cell31: 31|1@1+ (1,0) [0|1] "" Vector__XXX
 SG_ BmsDrainStatusA_Cell32: 32|1@1+ (1,0) [0|1] "" Vector__XXX
 SG_ BmsDrainStatusA_Cell33: 33|1@1+ (1,0) [0|1] "" Vector__XXX
 SG_ BmsDrainStatusA_Cell34: 34|1@1+ (1,0) [0|1] "" Vector__XXX
 SG_ BmsDrainStatusA_Cell35: 35|1@1+ (1,0) [0|1] "" Vector__XXX
 SG_ BmsDrainStatusA_Cell36: 36|1@1+ (1,0) [0|1] "" Vector__XXX
 SG_ BmsDrainStatusA_Cell37: 37|1@1+ (1,0) [0|1] "" Vector__XXX
 SG_ BmsDrainStatusA_Cell38: 38|1@1+ (1,0) [0|1] "" Vector__XXX
 SG_ BmsDrainStatusA_Cell39: 39|1@1+ (1,0) [0|1] "" Vector__XXX
 SG_ BmsDrainStatusA_Cell40: 40|1@1+ (1,0) [0|1] "" Vector__XXX
 SG_ BmsDrainStatusA_Cell41: 41|1@1+ (1,0) [0|1] "" Vector__XXX
 SG_ BmsDrainStatusA_Cell42: 42|1@1+ (1,0) [0|1] "" Vector__XXX
 SG_ BmsDrainStatusA_Cell43: 43|1@1+ (1,0) [0|1] "" Vector__XXX
 SG_ BmsDrainStatusA_Cell44: 44|1@1+ (1,0) [0|1] "" Vector__XXX
 SG_ BmsDrainStatusA_Cell45: 45|1@1+ (1,0) [0|1] "" Vector__XXX
 SG_ BmsDrainStatusA_Cell46: 46|1@1+ (1,0) [0|1] "" Vector__XXX
 SG_ BmsDrainStatusA_Cell47: 47|1@1+ (1,0) [0|1] "" Vector__XXX
 SG_ BmsDrainStatusA_Cell48: 48|1@1+ (1,0) [0|1] "" Vector__XXX
 SG_ BmsDrainStatusA_Cell49: 49|1@1+ (1,0) [0|1] "" Vector__XXX
 SG_ BmsDrainStatusA_Cell50: 50|1@1+ (1,0) [0|1] "" Vector__XXX
 SG_ BmsDrainStatusA_Cell51: 51|1@1+ (1,0) [0|1] "" Vector__XXX
 SG_ BmsDrainStatusA_Cell52: 52|1@1+ (1,0) [0|1] "" Vector__XXX
 SG_ BmsDrainStatusA_Cell53: 53|1@1+ (1,0) [0|1] "" Vector__XXX
 SG_ BmsDrainStatusA_Cell54: 54|1@1+ (1,0) [0|1] "" Vector__XXX
 SG_ BmsDrainStatusA_Cell55: 55|1@1+ (1,0) [0|1] "" Vector__XXX
 SG_ BmsDrainStatusA_Cell56: 56|1@1+ (1,0) [0|1] "" Vector__XXX
 SG_ BmsDrainStatusA_Cell57: 57|1@1+ (1,0) [0|1] "" Vector__XXX
 SG_ BmsDrainStatusA_Cell58: 58|1@1+ (1,0) [0|1] "" Vector__XXX
 SG_ BmsDrainStatusA_Cell59: 59|1@1+ (1,0) [0|1] "" Vector__XXX
 SG_ BmsDrainStatusA_Cell60: 60|1@1+ (1,0) [0|1] "" Vector__XXX
 SG_ BmsDrainStatusA_Cell61: 61|1@1+ (1,0) [0|1] "" Vector__XXX
 SG_ BmsDrainStatusA_Cell62: 62|1@1+ (1,0) [0|1] "" Vector__XXX
 SG_ BmsDrainStatusA_Cell63: 63|1@1+ (1,0) [0|1] "" Vector__XXX

BO_ 801 BmsDrainStatusB: 8 Bms
 SG_ BmsDrainStatusB_Cell64: 0|1@1+ (1,0) [0|1] "" Vector__XXX
 SG_ BmsDrainStatusB_Cell65: 1|1@1+ (1,0) [0|1] "" Vector__XXX
 SG_ BmsDrainStatusB_Cell66: 2|1@1+ (1,0) [0|1] "" Vector__XXX
 SG_ BmsDrainStatusB_Cell67: 3|1@1+ (1,0) [0|1] "" Vector__XXX
 SG_ BmsDrainStatusB_Cell68: 4|1@1+ (1,0) [0|1] "" Vector__XXX
 SG_ BmsDrainStatusB_Cell69: 5|1@1+ (1,0) [0|1] "" Vector__XXX
 SG_ BmsDrainStatusB_Cell70: 6|1@1+ (1,0) [0|1] "" Vector__XXX
 SG_ BmsDrainStatusB_Cell71: 7|1@1+ (1,0) [0|1] "" Vector__XXX
 SG_ BmsDrainStatusB_Cell72: 8|1@1+ (1,0) [0|1] "" Vector__XXX
 SG_ BmsDrainStatusB_Cell73: 9|1@1+ (1,0) [0|1] "" Vector__XXX
 SG_ BmsDrainStatusB_Cell74: 10|1@1+ (1,0) [0|1] "" Vector__XXX
 SG_ BmsDrainStatusB_Cell75: 11|1@1+ (1,0) [0|1] "" Vector__XXX
 SG_ BmsDrainStatusB_Cell76: 12|1@1+ (1,0) [0|1] "" Vector__XXX
 SG_ BmsDrainStatusB_Cell77: 13|1@1+ (1,0) [0|1] "" Vector__XXX
 SG_ BmsDrainStatusB_Cell78: 14|1@1+ (1,0) [0|1] "" Vector__XXX
 SG_ BmsDrainStatusB_Cell79: 15|1@1+ (1,0) [0|1] "" Vector__XXX
 SG_ BmsDrainStatusB_Cell80: 16|1@1+ (1,0) [0|1] "" Vector__XXX
 SG_ BmsDrainStatusB_Cell81: 17|1@1+ (1,0) [0|1] "" Vector__XXX
 SG_ BmsDrainStatusB_Cell82: 18|1@1+ (1,0) [0|1] "" Vector__XXX
 SG_ BmsDrainStatusB_Cell83: 19|1@1+ (1,0) [0|1] "" Vector__XXX
 SG_ BmsDrainStatusB_Cell84: 20|1@1+ (1,0) [0|1] "" Vector__XXX
 SG_ BmsDrainStatusB_Cell85: 21|1@1+ (1,0) [0|1] "" Vector__XXX
 SG_ BmsDrainStatusB_Cell86: 22|1@1+ (1,0) [0|1] "" Vector__XXX
 SG_ BmsDrainStatusB_Cell87: 23|1@1+ (1,0) [0|1] "" Vector__XXX
 SG_ BmsDrainStatusB_Cell88: 24|1@1+ (1,0) [0|1] "" Vector__XXX
 SG_ BmsDrainStatusB_Cell89: 25|1@1+ (1,0) [0|1] "" Vector__XXX

BO_ 900 BmsCurrent: 8 Bms
 SG_ BmsInstCurrentFilt : 0|32@1- (0.001,0) [-100|250] "A" Vector__XXX

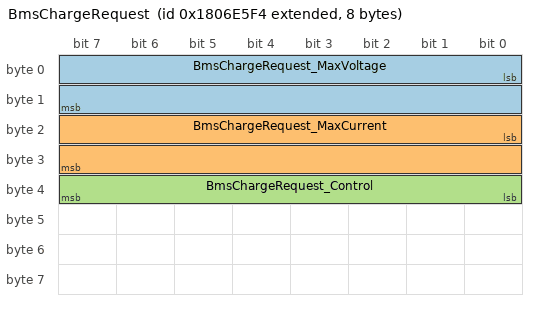
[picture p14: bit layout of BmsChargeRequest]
BO_ 2550588916 BmsChargeRequest: 8 Bms
 SG_ BmsChargeRequest_MaxVoltage: 0|16@1+ (0.1,0) [0|6553.3] "V" Vector__XXX
 SG_ BmsChargeRequest_MaxCurrent: 16|16@1+ (0.1,0) [0|6553.3] "A" Vector__XXX
 SG_ BmsChargeRequest_Control: 32|8@1+ (1,0) [0|1] "" Vector__XXX

BO_ 950 BmsHardFaultIndicator: 8 Bms
 SG_ BmsHardFaultIndicator_task: 0|4@1+ (1,0) [0|15] "" Vector__XXX

BO_ 951 BmsRef: 8 Bms
 SG_ BmsRef_mux M: 0|1@1+ (1,0) [0|1] "" Vector__XXX
 SG_ BmsRef_ref0 m0: 1|9@1+ (0.01,0) [0|5.12] "V" Vector__XXX
 SG_ BmsRef_ref1 m0: 10|9@1+ (0.01,0) [0|5.12] "V" Vector__XXX
 SG_ BmsRef_ref2 m0: 19|9@1+ (0.01,0) [0|5.12] "V" Vector__XXX
 SG_ BmsRef_ref3 m0: 28|9@1+ (0.01,0) [0|5.12] "V" Vector__XXX
 SG_ BmsRef_ref4 m0: 37|9@1+ (0.01,0) [0|5.12] "V" Vector__XXX
 SG_ BmsRef_ref5 m0: 46|9@1+ (0.01,0) [0|5.12] "V" Vector__XXX
 SG_ BmsRef_ref6 m1: 1|9@1+ (0.01,0) [0|5.12] "V" Vector__XXX
 SG_ BmsRef_ref7 m1: 10|9@1+ (0.01,0) [0|5.12] "V" Vector__XXX
 SG_ BmsRef_ref8 m1: 19|9@1+ (0.01,0) [0|5.12] "V" Vector__XXX
 SG_ BmsRef_ref9 m1: 28|9@1+ (0.01,0) [0|5.12] "V" Vector__XXX
 SG_ BmsRef_ref10 m1: 37|9@1+ (0.01,0) [0|5.12] "V" Vector__XXX
 SG_ BmsRef_ref11 m1: 46|9@1+ (0.01,0) [0|5.12] "V" Vector__XXX

VAL_ 701 BmsFaultAlert_code 0 "FaultCode_SLAVE_COMM_CELLS" 1 "FaultCode_SLAVE_COMM_TEMPS" 2 "FaultCode_SLAVE_COMM_DRAIN_REQUEST" 3 "FaultCode_CURRENT_SENSOR_COMM" 4 "FaultCode_OVER_CURRENT" 5 "FaultCode_CELL_VOLTAGE_IRRATIONAL" 6 "FaultCode_CELL_VOLTAGE_DIFF" 7 "Faultcode_OUT_OF_JUICE" 8 "FaultCode_TEMPERATURE_IRRATIONAL" 9 "FaultCode_OVER_TEMP" 10 "FaultCode_DRAIN_FAILURE";
VAL_ 311 VcFaultAlert_code 0 "FaultCode_BRAKE_SENSOR_IRRATIONAL" 1 "FaultCode_ACCELERATOR_SENSOR_IRRATIONAL" 2 "FaultCode_APPS_SENSOR_DISAGREEMENT" 3 "FaultCode_APPS_DOUBLE_PEDAL";
VAL_ 600 BmsStatus_ChargeState 0 "ChargeState_DISCONNECTED" 1 "ChargeState_CONNECTED_COMPLETE" 2 "ChargeState_CONNECTED_BALANCING" 3 "ChargeState_CONNECTED_CHARGING" 4 "ChargeState_CONNECTED_BALANCE_SENSING";
VAL_ 950 BmsHardFaultIndicator_task 0 "unknown" 1 "task_1Hz" 2 "task_10Hz" 3 "task_1kHz";

CM_ BU_ INV "The Cascadia Motion inverter";
CM_ BU_ U2C "Delphi DC/DC Converter";
CM_ BU_ VCU "The system vehicle control unit";
CM_ BU_ BMS "BMS Master";
CM_ SG_ 173 D4_Iq_Command "The commanded Q-axis current";
CM_ SG_ 173 D3_Id_Command "The commanded D-axis current";
CM_ SG_ 173 D2_Flux_Weakening_Output "This is the current output of the flux regulator.";
CM_ SG_ 173 D1_Modulation_Index "This is the modulation index. The scale factor is x100. To get the actual modulation index divide the value by 100.";
CM_ SG_ 172 D3_Power_On_Timer "Updated every 3 msec. This will roll over in approximately 150 days!";
CM_ SG_ 172 D2_Torque_Feedback "Estimated motor torque feedback";
CM_ SG_ 172 D1_Commanded_Torque "The commanded Torque";
CM_ BO_ 194 "The inverter response to each Parameter message that is received.";
CM_ SG_ 194 D2_Write_Success "0=Write failure, 1=Success";
CM_ SG_ 194 D3_Data_Response "All EEPROM data is 16 bits and is contained in bytes 4 and 5. Bytes 6 and 7 should be ignored.";
CM_ SG_ 194 D1_Parameter_Address_Response "Valid EEPROM Parameter CAN addresses are between 100 and 499.";
CM_ BO_ 193 "Parameter Message sent as needed by VCU to request info, change EEPROM, or command a function.";
CM_ SG_ 193 D3_Data_Command "All EEPROM data is 16 bits and is contained in bytes 4 and 5.";
CM_ SG_ 193 D2_Read_Write_Command "0=Read, 1=Write";
CM_ SG_ 193 D1_Parameter_Address_Command "Valid EEPROM Parameter CAN addresses are between 100 and 499.";
CM_ BO_ 192 "The command message is used to transmit data to the controller. This message is sent from a user supplied external controller to the PMxxx controller.";
CM_ SG_ 192 Inverter_Enable "0=Inverter OFF, 1 = Inverter ON";
CM_ SG_ 192 Direction_Command "0=CW, 1=CCW as veiwed from the shaft end of the motor";
CM_ SG_ 192 Speed_Command "Speed commandused when in speed mode";
CM_ SG_ 192 Torque_Command "Torque command when in torque mode";
CM_ SG_ 192 Inverter_Discharge "0=Discharge Disable,
=Discharge Enable";
CM_ SG_ 192 Torque_Limit_Command "Torque Limit, set to 0 to keep default";
CM_ SG_ 192 Speed_Mode_Enable "0 = No change to mode, 1 = change to speed mode from torque mode";
CM_ SG_ 192 RollingCounter "Rolling Counter command";
CM_ SG_ 171 D4_Run_Fault_Hi "Each bit represents a fault. Please refer to PM100 Users Manual for details.";
CM_ SG_ 171 D2_Post_Fault_Hi "Each bit represents a fault. Please refer to PM100 Users Manual for details.";
CM_ SG_ 171 D3_Run_Fault_Lo "Each bit represents a fault. Please refer to PM100 Users Manual for details.";
CM_ SG_ 171 D1_Post_Fault_Lo "Each bit represents a fault. Please refer to PM100 Users Manual for details.";
CM_ SG_ 170 D7_Direction_Command "1 = Forward
0 = 'Reverse' if inverter enabled  & 'Stopped' if inverter is disabled";
CM_ SG_ 170 D6_Inverter_Enable_State "0=Inverter Disabled, 
1=Inverter Enabled";
CM_ SG_ 170 D3_Relay_3_Status "0=OFF, 1=ON";
CM_ SG_ 170 D3_Relay_4_Status "0=OFF, 1=ON";
CM_ SG_ 170 D3_Relay_2_Status "0=OFF, 1=ON";
CM_ SG_ 170 D4_Inverter_Run_Mode "0=Torque Mode, 1=Speed Mode";
CM_ SG_ 170 D5_Inverter_Command_Mode "0=CAN mode, 1=VSM mode";
CM_ SG_ 170 D3_Relay_1_Status "0=OFF, 1=ON";
CM_ SG_ 170 D2_Inverter_State "Different states for the inverter state machine";
CM_ SG_ 170 D1_VSM_State "Different states for the vehicle state machine";
CM_ SG_ 170 D6_Inverter_Enable_Lockout "0=Lockout Disabled, 1=Lockout Enabled";
CM_ SG_ 170 D4_Inverter_Discharge_State "0 = Disabled, 1 = Enabled, 2 = Speed Check, 3 = Active, 4 = Complete";
CM_ SG_ 170 D3_Relay_5_Status "0=OFF, 1=ON";
CM_ SG_ 170 D3_Relay_6_Status "0=OFF, 1=ON";
CM_ SG_ 170 D7_BMS_Active "0 = BMS Not Active, 1 = BMS Active";
CM_ SG_ 170 D7_BMS_Torque_Limiting "0 = Not Limiting, 1 = Limiting";
CM_ SG_ 170 D7_Max_Speed_Limiting "0 = Not Limiting, 1 = torque limiting due to maximum speed";
CM_ SG_ 170 D7_Low_Speed_Limiting "0 = Not Limiting, 1 = Current limiting due to low motor speed";
CM_ SG_ 170 D5_Rolling_Counter "The current rolling counter value.";
CM_ SG_ 170 D1_PWM_Frequency "The inverter PWM frequency";
CM_ SG_ 170 D6_Start_Mode_Active "If in Key Switch Mode 1 then indicates status of Start input being applied.  0 = not active, 1 = active";
CM_ SG_ 169 D4_Reference_Voltage_12_0 "12V Input Voltage";
CM_ SG_ 169 D3_Reference_Voltage_5_0 "Transducer voltage";
CM_ SG_ 169 D2_Reference_Voltage_2_5 "Internal reference voltage";
CM_ SG_ 169 D1_Reference_Voltage_1_5 "Internal reference voltage";
CM_ SG_ 168 D4_Iq "The measured Iq current";
CM_ SG_ 168 D3_Id "The measured Id current";
CM_ SG_ 168 D2_Flux_Feedback "The estimated flux";
CM_ SG_ 168 D1_Flux_Command "The commanded flux";
CM_ SG_ 167 D4_VBC_Vq_Voltage "Measured value of the voltage between Phase B and Phase C";
CM_ SG_ 167 D3_VAB_Vd_Voltage "Measured value of the voltage betwen phase A and Phase B";
CM_ SG_ 167 D2_Output_Voltage "The calculated value of the output voltage, in peak line-neutral volts";
CM_ SG_ 167 D1_DC_Bus_Voltage "The actual measured value of the DC bus voltage";
CM_ SG_ 166 D4_DC_Bus_Current "The Calculated DC Bus Current";
CM_ SG_ 166 D3_Phase_C_Current "The measured value of Phase C current";
CM_ SG_ 166 D2_Phase_B_Current "The measured value of Phase B current";
CM_ SG_ 166 D1_Phase_A_Current "The measured value of Phase A current";
CM_ SG_ 165 D4_Delta_Resolver_Filtered "Used in calibration of resolver angle adjustment.";
CM_ SG_ 165 D3_Electrical_Output_Frequency "The actual electrical frequency of the inverter";
CM_ SG_ 165 D2_Motor_Speed "The measured speed of the motor";
CM_ SG_ 165 D1_Motor_Angle_Electrical "The Electrical Angle of the motor as read by the encoder or resolver";
CM_ SG_ 164 D5_Digital_Input_5 "Status of Digital Input #5";
CM_ SG_ 164 D4_Digital_Input_4 "Status of Digital Input #4";
CM_ SG_ 164 D3_Digital_Input_3 "Status of Digital Input #3";
CM_ SG_ 164 D2_Digital_Input_2 "Status of Digital Input #2";
CM_ SG_ 164 D1_Digital_Input_1 "Status of Digital Input #1";
CM_ SG_ 164 D6_Digital_Input_6 "Status of Digital Input #6";
CM_ SG_ 164 D7_Digital_Input_7 "Status of Digital Input #7";
CM_ SG_ 164 D8_Digital_Input_8 "Status of Digital Input #8";
CM_ SG_ 163 D4_Analog_Input_4 "Voltage on Analog Input #4";
CM_ SG_ 163 D3_Analog_Input_3 "Voltage on Analog Input #3";
CM_ SG_ 163 D2_Analog_Input_2 "Voltage on Analog Input #2";
CM_ SG_ 163 D1_Analog_Input_1 "Voltage on Analog Input #1";
CM_ SG_ 163 D5_Analog_Input_5 "Voltage on Analog Input #5";
CM_ SG_ 163 D6_Analog_Input_6 "Voltage on Analog Input #6";
CM_ SG_ 162 D4_Torque_Shudder "Shudder compensation value of torque";
CM_ SG_ 162 D3_Motor_Temperature "Motor Temperature Sensor";
CM_ SG_ 162 D2_RTD5_Temperature "RTD 5 (PT1000) Temperature (Gen 2 only)";
CM_ SG_ 162 D1_RTD4_Temperature "RTD 4 (PT1000) Temperature (Gen 2 only)";
CM_ SG_ 161 D4_RTD3_Temperature "RTD input 3 (PT1000) Temperature (Gen 2 only)";
CM_ SG_ 161 D3_RTD2_Temperature "RTD input 2 (PT1000) Temperature";
CM_ SG_ 161 D2_RTD1_Temperature "RTD input 1 (PT1000) Temperature";
CM_ SG_ 161 D1_Control_Board_Temperature "Control Board Temperature";
CM_ SG_ 160 D4_Gate_Driver_Board "Gate Driver Board Temperature";
CM_ SG_ 160 D3_Module_C "IGBT Module C Temperature";
CM_ SG_ 160 D2_Module_B "IGBT Module B Temperature";
CM_ SG_ 160 D1_Module_A "IGBT Module A Temperature";
CM_ BO_ 471 "Enable message sent to Delphi DC/DC converter.";
CM_ BO_ 469 "Response from Delphi DC/DC converter.";
CM_ BO_ 514 "Message sent by BMS for inverter DC current limiting.";
CM_ SG_ 514 D1_Max_Discharge_Current "Maximum discharge current from BMS";
CM_ SG_ 514 D2_Max_Charge_Current "Maximum charge current from BMS";
CM_ BO_ 176 "To enable fast message set CAN ACTIVE MSGS HI WORD to 0xFFFE.  Setting to default value of 0xFFFF will disable the fast message.";
CM_ SG_ 176 Fast_Torque_Command "The commanded torque";
CM_ SG_ 176 Fast_Torque_Feedback "The estimated torque";
CM_ SG_ 176 Fast_Motor_Speed "Motor speed";
CM_ SG_ 176 Fast_DC_Bus_Voltage "DC Bus Voltage";
BA_DEF_ BO_  "GenMsgCycleTime" INT 0 100000;
BA_DEF_  "BusType" STRING ;
BA_DEF_DEF_  "GenMsgCycleTime" 0;
BA_DEF_DEF_  "BusType" "CAN";
BA_ "GenMsgCycleTime" BO_ 172 10;
BA_ "GenMsgCycleTime" BO_ 192 5;
BA_ "GenMsgCycleTime" BO_ 171 100;
BA_ "GenMsgCycleTime" BO_ 170 100;
BA_ "GenMsgCycleTime" BO_ 169 100;
BA_ "GenMsgCycleTime" BO_ 168 10;
BA_ "GenMsgCycleTime" BO_ 167 10;
BA_ "GenMsgCycleTime" BO_ 166 10;
BA_ "GenMsgCycleTime" BO_ 165 10;
BA_ "GenMsgCycleTime" BO_ 164 10;
BA_ "GenMsgCycleTime" BO_ 163 10;
BA_ "GenMsgCycleTime" BO_ 162 100;
BA_ "GenMsgCycleTime" BO_ 161 100;
BA_ "GenMsgCycleTime" BO_ 160 100;
BA_ "GenMsgCycleTime" BO_ 176 3;
VAL_ 192 Inverter_Enable 0 "Turn the inverter OFF" 1 "Turn the Inverter ON" ;
VAL_ 192 Direction_Command 0 "CW" 1 "CCW" ;
VAL_ 192 Inverter_Discharge 0 "Discharge Disable" 1 "Discharge Enable (if EEPROM parameter is set)" ;
VAL_ 170 D2_Inverter_State 0 "Power up" 1 "Stop" 2 "Open Loop" 3 "Closed Loop" 4 "Internal State" 5 "Internal State" 6 "Internal State" 7 "Internal State" 8 "Idle Run" 9 "Idle Stop" 10 "Internal State" 11 "Intern State" 12 "Internal State" ;
VAL_ 170 D1_VSM_State 0 "VSM Start State" 1 "Pre-Charge Init state" 2 "pre-charge active state" 3 "pre-charge complete state" 4 "VSM wait state" 5 "VSM ready state" 6 "Motor Running State" 7 "blink fault code state" 14 "Shutdown state for Key Switch Mode 1" 15 "Reset the inverter" ;
